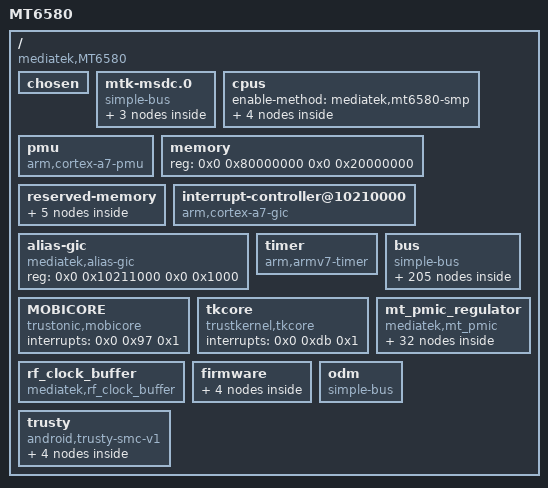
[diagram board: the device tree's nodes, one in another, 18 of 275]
/dts-v1/;

/ {
	model = "MT6580";
	compatible = "mediatek,MT6580";
	interrupt-parent = <0x1>;
	#address-cells = <0x2>;
	#size-cells = <0x2>;

	chosen {
		bootargs = "console=tty0 console=ttyMT0,921600n1 root=/dev/ram initrd=0x84000000,0x400000 loglevel=8";
		linux,phandle = <0x1e>;
		phandle = <0x1e>;
	};

	mtk-msdc.0 {
		compatible = "simple-bus";
		#address-cells = <0x1>;
		#size-cells = <0x1>;
		ranges = <0x0 0x0 0x0 0xffffffff>;

		msdc0@11120000 {
			compatible = "mediatek,mt6580-mmc";
			reg = <0x11120000 0x10000 0x10001e84 0x2>;
			interrupts = <0x0 0x26 0x8>;
			status = "disabled";
			linux,phandle = <0x1f>;
			phandle = <0x1f>;
		};

		msdc1@11130000 {
			compatible = "mediatek,mt6580-mmc";
			reg = <0x11130000 0x10000 0x10001e84 0x2>;
			interrupts = <0x0 0x27 0x8>;
			cd-gpios = <0x2 0x3 0x0>;
			status = "disabled";
			linux,phandle = <0x20>;
			phandle = <0x20>;
		};

		default {
			compatible = "mediatek,msdc1_ins-eint";
			linux,phandle = <0x21>;
			phandle = <0x21>;
		};
	};

	cpus {
		#address-cells = <0x1>;
		#size-cells = <0x0>;
		enable-method = "mediatek,mt6580-smp";

		cpu@0 {
			device_type = "cpu";
			compatible = "arm,cortex-a7";
			reg = <0x0>;
			clock-frequency = <0x6553f100>;
			linux,phandle = <0x22>;
			phandle = <0x22>;
		};

		cpu@1 {
			device_type = "cpu";
			compatible = "arm,cortex-a7";
			reg = <0x1>;
			clock-frequency = <0x6553f100>;
			linux,phandle = <0x23>;
			phandle = <0x23>;
		};

		cpu@2 {
			device_type = "cpu";
			compatible = "arm,cortex-a7";
			reg = <0x2>;
			clock-frequency = <0x6553f100>;
			linux,phandle = <0x24>;
			phandle = <0x24>;
		};

		cpu@3 {
			device_type = "cpu";
			compatible = "arm,cortex-a7";
			reg = <0x3>;
			clock-frequency = <0x6553f100>;
			linux,phandle = <0x25>;
			phandle = <0x25>;
		};
	};

	pmu {
		compatible = "arm,cortex-a7-pmu";
		interrupts = <0x0 0x4 0x8 0x0 0x5 0x8 0x0 0x6 0x8 0x0 0x7 0x8>;
	};

	memory {
		device_type = "memory";
		reg = <0x0 0x80000000 0x0 0x20000000>;
	};

	reserved-memory {
		#address-cells = <0x2>;
		#size-cells = <0x2>;
		ranges;
		linux,phandle = <0x26>;
		phandle = <0x26>;

		consys-reserve-memory {
			compatible = "mediatek,consys-reserve-memory";
			no-map;
			size = <0x0 0x200000>;
			alignment = <0x0 0x200000>;
		};

		reserve-memory-ccci_md1 {
			compatible = "mediatek,reserve-memory-ccci_md1";
			no-map;
			size = <0x0 0x1800000>;
			alignment = <0x0 0x2000000>;
			alloc-ranges = <0x0 0x80000000 0x0 0x80000000>;
		};

		pstore-reserved-memory@83f10000 {
			compatible = "mediatek,pstore";
			reg = <0x0 0x83f10000 0x0 0xe0000>;
		};

		ram_console-reserved-memory@83f00000 {
			compatible = "mediatek,ram_console";
			reg = <0x0 0x83f00000 0x0 0x10000>;
		};

		minirdump-reserved-memory@83ff0000 {
			compatible = "mediatek, minirdump";
			reg = <0x0 0x83ff0000 0x0 0x10000>;
		};
	};

	interrupt-controller@10210000 {
		compatible = "arm,cortex-a7-gic";
		#interrupt-cells = <0x3>;
		#address-cells = <0x0>;
		interrupt-controller;
		reg = <0x0 0x10211000 0x0 0x1000 0x0 0x10212000 0x0 0x1000 0x0 0x10200100 0x0 0x1000>;
		interrupts = <0x1 0x9 0xf04>;
		linux,phandle = <0x1>;
		phandle = <0x1>;
	};

	alias-gic {
		compatible = "mediatek,alias-gic";
		reg = <0x0 0x10211000 0x0 0x1000>;
	};

	timer {
		compatible = "arm,armv7-timer";
		interrupts = <0x1 0xd 0x8 0x1 0xe 0x8 0x1 0xb 0x8 0x1 0xa 0x8>;
		clock-frequency = <0xc65d40>;
	};

	bus {
		compatible = "simple-bus";
		#address-cells = <0x1>;
		#size-cells = <0x1>;
		ranges = <0x0 0x0 0x0 0xffffffff>;
		linux,phandle = <0x27>;
		phandle = <0x27>;

		chipid@08000000 {
			compatible = "mediatek,chipid";
			reg = <0x8000000 0x4 0x8000004 0x4 0x8000008 0x4 0x800000c 0x4>;
		};

		TOPCKGEN@0x10000000 {
			compatible = "mediatek,TOPCKGEN";
			reg = <0x10000000 0x1000>;
		};

		INFRACFG_AO@0x10001000 {
			compatible = "mediatek,INFRACFG_AO";
			reg = <0x10001000 0x1000>;
		};

		bat_meter {
			compatible = "mediatek,bat_meter";
			linux,phandle = <0x28>;
			phandle = <0x28>;
		};

		BAT_NOTIFY {
			compatible = "mediatek,bat_notify";
		};

		bat_comm {
			compatible = "mediatek,battery";
			linux,phandle = <0x29>;
			phandle = <0x29>;
		};

		keypad@10002000 {
			compatible = "mediatek,mt6580-keypad";
			reg = <0x10002000 0x1000>;
			interrupts = <0x0 0x6d 0x2>;
			linux,phandle = <0x2a>;
			phandle = <0x2a>;
		};

		PERICFG@0x10003000 {
			compatible = "mediatek,PERICFG";
			reg = <0x10003000 0x1000>;
		};

		RESERVED@0x10004000 {
			compatible = "mediatek,RESERVED";
			reg = <0x10004000 0x1000>;
		};

		gpio {
			compatible = "mediatek,gpio_usage_mapping";
			linux,phandle = <0x2b>;
			phandle = <0x2b>;
		};

		gpio@0x10005000 {
			compatible = "mediatek,gpio";
			reg = <0x10005000 0x1000>;
			linux,phandle = <0x2c>;
			phandle = <0x2c>;
		};

		SLEEP@0x10006000 {
			compatible = "mediatek,SLEEP";
			reg = <0x10006000 0x1000>;
			interrupts = <0x0 0x58 0x8 0x0 0x59 0x8 0x0 0x5a 0x8 0x0 0x5b 0x8>;
		};

		TOPRGU@0x10007000 {
			compatible = "mediatek,TOPRGU";
			reg = <0x10007000 0x1000>;
			interrupts = <0x0 0x9d 0x2>;
		};

		APXGPT@0x10008000 {
			compatible = "mediatek,APXGPT";
			reg = <0x10008000 0x1000>;
			interrupts = <0x0 0x5c 0x8>;
			clock-frequency = <0xc65d40>;
		};

		EFUSEC@0x10009000 {
			compatible = "mediatek,EFUSEC";
			reg = <0x10009000 0x1000>;
		};

		hacc@0x1000A000 {
			compatible = "mediatek,hacc";
			reg = <0x1000a000 0x1000>;
			interrupts = <0x0 0x6e 0x0>;
		};

		cpu_dbgapb@10170000 {
			compatible = "mediatek,hw_dbg";
			num = <0x4>;
			reg = <0x10170000 0x2000 0x10172000 0x2000 0x10174000 0x2000 0x10176000 0x2000>;
			linux,phandle = <0x2d>;
			phandle = <0x2d>;
		};

		eintc@1000b000 {
			compatible = "mediatek,mt-eic";
			reg = <0x1000b000 0x1000>;
			interrupts = <0x0 0x5e 0x4>;
			#interrupt-cells = <0x2>;
			interrupt-controller;
			mediatek,max_eint_num = <0x1a>;
			mediatek,mapping_table_entry = <0x53>;
			mediatek,mapping_table = <0x0 0x0 0x1 0x1 0x2 0x2 0x3 0x3 0x4 0x4 0x5 0x5 0x6 0x6 0x7 0x7 0x8 0x8 0x9 0x9 0xa 0xa 0xb 0xb 0xc 0xc 0xd 0xd 0xe 0xe 0xf 0xf 0x10 0x0 0x11 0x1 0x12 0x2 0x13 0x3 0x14 0x4 0x15 0x5 0x16 0x6 0x17 0x7 0x18 0x8 0x19 0x9 0x1a 0xa 0x1b 0xb 0x1c 0xc 0x1d 0xd 0x1e 0xe 0x1f 0xf 0x20 0x0 0x21 0x1 0x22 0x2 0x23 0x3 0x24 0x4 0x25 0x5 0x26 0x6 0x27 0x7 0x28 0x8 0x29 0x9 0x2a 0xa 0x2b 0xb 0x2c 0xc 0x2d 0xd 0x2e 0xe 0x2f 0xf 0x30 0x0 0x31 0x1 0x32 0x2 0x33 0x3 0x34 0x3 0x35 0x4 0x36 0x5 0x37 0x6 0x38 0x7 0x39 0x8 0x3a 0xa 0x3b 0xb 0x3c 0xc 0x3d 0xd 0x3e 0xe 0x3f 0xf 0x40 0x0 0x41 0x1 0x42 0x2 0x43 0x3 0x44 0x10 0x45 0x4 0x46 0x5 0x47 0x6 0x48 0x7 0x49 0x8 0x4a 0x9 0x4b 0xa 0x4c 0xb 0x4d 0xc 0x4e 0xd 0x51 0x0 0x52 0x1 0x53 0x2 0x54 0x3>;
			mediatek,builtin_entry = <0xb>;
			mediatek,builtin_mapping = <0x0 0x3 0x14 0x1 0x3 0x12 0x7 0x4 0x14 0x8 0x4 0x12 0x9 0x3 0x14 0xa 0x3 0x12 0x18 0x5 0x14 0x19 0x5 0x12 0x4d 0x2 0x14 0x4e 0x2 0x12 0xd 0x1 0x11>;
			linux,phandle = <0x3>;
			phandle = <0x3>;

			pmic@13 {
				compatible = "mediatek, pmic-eint";
				interrupt-parent = <0x3>;
				interrupts = <0xd 0x4>;
				debounce = <0xd 0x3e8>;
			};
		};

		ap_ccif0@1000C000 {
			compatible = "mediatek,ap_ccif0";
			reg = <0x1000c000 0x1000 0x1000d000 0x1000>;
			interrupts = <0x0 0x5d 0x8 0x0 0x98 0x2>;
			mediatek,ccif_capability = <0x2>;
			mediatek,md_smem_size = <0x200000>;
			linux,phandle = <0x2e>;
			phandle = <0x2e>;
		};

		MCUSYS_CFGREG@0x1020000 {
			compatible = "mediatek,MCUSYS_CFGREG_BASE";
			reg = <0x1020000 0x200>;
		};

		mcucfg@10200000 {
			compatible = "mediatek,mt6580-mcucfg";
			reg = <0x10200000 0x200>;
			linux,phandle = <0x2f>;
			phandle = <0x2f>;
		};

		AES@0x1000E000 {
			compatible = "mediatek,AES";
			reg = <0x1000e000 0x1000>;
		};

		PWRAP@0x1000F000 {
			compatible = "mediatek,PWRAP";
			reg = <0x1000f000 0x1000>;
			interrupts = <0x0 0x6c 0x0>;
		};

		DEVAPC_AO@0x10010000 {
			compatible = "mediatek,DEVAPC_AO";
			reg = <0x10010000 0x1000>;
		};

		MIPI_CONFG@0x10011000 {
			compatible = "mediatek,MIPI_CONFG";
			reg = <0x10011000 0x1000>;
		};

		INFRA_MBIST@0x10012000 {
			compatible = "mediatek,INFRA_MBIST";
			reg = <0x10012000 0x1000>;
		};

		RESERVED@0x10013000 {
			compatible = "mediatek,RESERVED";
			reg = <0x10013000 0x1000>;
		};

		IOCFG_T@0x10014000 {
			compatible = "mediatek,IOCFG_T";
			reg = <0x10014000 0x1000>;
		};

		IOCFG_B@0x10015000 {
			compatible = "mediatek,IOCFG_B";
			reg = <0x10015000 0x1000>;
		};

		IOCFG_L@0x10016000 {
			compatible = "mediatek,IOCFG_L";
			reg = <0x10016000 0x1000>;
		};

		IOCFG_R@0x10017000 {
			compatible = "mediatek,IOCFG_R";
			reg = <0x10017000 0x1000>;
		};

		APMIXED@0x10018000 {
			compatible = "mediatek,APMIXED";
			reg = <0x10018000 0x1000>;
		};

		MCUCFG@0x10200000 {
			compatible = "mediatek,MCUCFG";
			reg = <0x10200000 0x1000>;
		};

		INFRACFG@0x10201000 {
			compatible = "mediatek,INFRACFG";
			reg = <0x10201000 0x1000>;
		};

		sys_cirq@10202000 {
			compatible = "mediatek,mt6580-sys_cirq", "mediatek,mt6735-sys_cirq";
			reg = <0x10202000 0x1000>;
			interrupts = <0x0 0x9e 0x8>;
			mediatek,cirq_num = <0x7e>;
			mediatek,spi_start_offset = <0x20>;
			linux,phandle = <0x30>;
			phandle = <0x30>;
		};

		m4u@10203000 {
			cell-index = <0x0>;
			compatible = "mediatek,m4u";
			reg = <0x10203000 0x1000>;
			interrupts = <0x0 0x51 0x8>;
		};

		DEVAPC@0x10204000 {
			compatible = "mediatek,DEVAPC";
			reg = <0x10204000 0x1000>;
			interrupts = <0x0 0x4a 0x8>;
		};

		EMI@0x10205000 {
			compatible = "mediatek,EMI";
			reg = <0x10205000 0x1000>;
			interrupts = <0x0 0x4c 0x4>;
		};

		DRAMC_NAO@0x10206000 {
			compatible = "mediatek,DRAMC_NAO";
			reg = <0x10206000 0x1000>;
		};

		DRAMC0@0x10207000 {
			compatible = "mediatek,DRAMC0";
			reg = <0x10207000 0x1000>;
		};

		DDRPHY@0x10208000 {
			compatible = "mediatek,DDRPHY";
			reg = <0x10208000 0x1000>;
		};

		SRAMROM@0x10209000 {
			compatible = "mediatek,SRAMROM";
			reg = <0x10209000 0x1000>;
		};

		gce@1020a000 {
			compatible = "mediatek,gce";
			reg = <0x1020a000 0x1000>;
			interrupts = <0x0 0x55 0x8 0x0 0x56 0x8>;
			disp_mutex_reg = <0x14015000 0x1000>;
			g3d_config_base = <0x13000000 0x0 0xffff0000>;
			mmsys_config_base = <0x14000000 0x1 0xffff0000>;
			disp_dither_base = <0x14010000 0x2 0xffff0000>;
			mm_na_base = <0x14020000 0x3 0xffff0000>;
			imgsys_base = <0x15000000 0x4 0xffff0000>;
			vdec_gcon_base = <0x16000000 0x5 0xffff0000>;
			venc_gcon_base = <0x17000000 0x6 0xffff0000>;
			conn_peri_base = <0x18000000 0x7 0xffff0000>;
			topckgen_base = <0x10000000 0x8 0xffff0000>;
			kp_base = <0x10010000 0x9 0xffff0000>;
			scp_sram_base = <0x10020000 0xa 0xffff0000>;
			infra_na3_base = <0x10030000 0xb 0xffff0000>;
			infra_na4_base = <0x10040000 0xc 0xffff0000>;
			scp_base = <0x10050000 0xd 0xffff0000>;
			mcucfg_base = <0x10200000 0xe 0xffff0000>;
			gcpu_base = <0x10210000 0xf 0xffff0000>;
			usb0_base = <0x11200000 0x10 0xffff0000>;
			usb_sif_base = <0x11210000 0x11 0xffff0000>;
			audio_base = <0x11220000 0x12 0xffff0000>;
			msdc0_base = <0x11230000 0x13 0xffff0000>;
			msdc1_base = <0x11240000 0x14 0xffff0000>;
			msdc2_base = <0x11250000 0x15 0xffff0000>;
			msdc3_base = <0x11260000 0x16 0xffff0000>;
			pwm_sw_base = <0x1100f000 0x63 0xfffff000>;
			mdp_rdma0_sof = <0x0>;
			mdp_rsz0_sof = <0x1>;
			mdp_rsz1_sof = <0x2>;
			mdp_tdshp_sof = <0x3>;
			mdp_wdma_sof = <0x4>;
			mdp_wrot_sof = <0x5>;
			disp_ovl0_sof = <0x6>;
			disp_rdma0_sof = <0x8>;
			disp_wdma0_sof = <0xa>;
			disp_color_sof = <0xc>;
			disp_aal_sof = <0xd>;
			disp_gamma_sof = <0xe>;
			disp_dither_sof = <0xf>;
			disp_pwm0_sof = <0x11>;
			mdp_rdma0_frame_done = <0x12>;
			mdp_rsz0_frame_done = <0x13>;
			mdp_rsz1_frame_done = <0x14>;
			mdp_tdshp_frame_done = <0x15>;
			mdp_wdma_frame_done = <0x16>;
			mdp_wrot_write_frame_done = <0x17>;
			mdp_wrot_read_frame_done = <0x18>;
			disp_ovl0_frame_done = <0x19>;
			disp_rdma0_frame_done = <0x1b>;
			disp_wdma0_frame_done = <0x1d>;
			disp_color_frame_done = <0x1f>;
			disp_aal_frame_done = <0x20>;
			disp_gamma_frame_done = <0x21>;
			disp_dither_frame_done = <0x22>;
			disp_dsi0_frame_done = <0x25>;
			stream_done_0 = <0x26>;
			stream_done_1 = <0x27>;
			stream_done_2 = <0x28>;
			stream_done_3 = <0x29>;
			stream_done_4 = <0x2a>;
			stream_done_5 = <0x2b>;
			stream_done_6 = <0x2c>;
			stream_done_7 = <0x2d>;
			stream_done_8 = <0x2e>;
			stream_done_9 = <0x2f>;
			buf_underrun_event_0 = <0x30>;
			dsi0_te_event = <0x32>;
			isp_frame_done_p2_1 = <0x42>;
			isp_frame_done_p2_0 = <0x43>;
			seninf_cam0_fifo_full = <0x49>;
			apxgpt2_count = <0x10008028>;
		};

		bus_dbg@1020b000 {
			compatible = "mediatek,bus_dbg-v2";
			reg = <0x1020b000 0x1000>;
			interrupts = <0x0 0x49 0x8>;
			two_stage_timeout = <0x1>;
		};

		TRNG@0x1020C000 {
			compatible = "mediatek,TRNG";
			reg = <0x1020c000 0x1000>;
			interrupts = <0x0 0x57 0x8>;
		};

		MCUCFG_BIU@0x1020D000 {
			compatible = "mediatek,MCUCFG_BIU";
			reg = <0x1020d000 0x1000>;
		};

		DBGSYS_DEM@0x1011A000 {
			compatible = "mediatek,DBGSYS_DEM";
			reg = <0x1011a000 0x1000>;
		};

		DBGSYS_CTI@0x10112000 {
			compatible = "mediatek,DBGSYS_CTI";
			reg = <0x10112000 0x1000>;
		};

		DBGSYS_DAPROM@0x10110000 {
			compatible = "mediatek,DBGSYS_DAPROM";
			reg = <0x10110000 0x1000>;
		};

		DBGSYS_CPU@0x10160000 {
			compatible = "mediatek,DBGSYS_CPU";
			reg = <0x10160000 0x20000>;
		};

		DBGSYS_MDSYS@0x10120000 {
			compatible = "mediatek,DBGSYS_MDSYS";
			reg = <0x10120000 0x10000>;
		};

		dma@0x11000000 {
			compatible = "mediatek,ap_dma";
			reg = <0x11000000 0x1000>;
			interrupts = <0x0 0x30 0x8>;
			linux,phandle = <0x31>;
			phandle = <0x31>;
		};

		NFI@0x11001000 {
			compatible = "mediatek,NFI";
			reg = <0x11001000 0x1000>;
			interrupts = <0x0 0x2f 0x8>;
		};

		NFIECC@0x11002000 {
			compatible = "mediatek,NFIECC";
			reg = <0x11002000 0x1000>;
			interrupts = <0x0 0x2e 0x8>;
		};

		adc_hw@11003000 {
			compatible = "mediatek,mt6735-auxadc";
			reg = <0x11003000 0x1000>;
			interrupts = <0x0 0x23 0x2>;
			linux,phandle = <0x32>;
			phandle = <0x32>;
		};

		FHCTL@0x11004000 {
			compatible = "mediatek,FHCTL";
			reg = <0x11004000 0x1000>;
		};

		AP_UART0@0x11005000 {
			cell-index = <0x0>;
			compatible = "mediatek,AP_UART0";
			reg = <0x11005000 0x1000>;
			interrupts = <0x0 0x2c 0x8>;
		};

		AP_UART1@0x11006000 {
			cell-index = <0x1>;
			compatible = "mediatek,AP_UART1";
			reg = <0x11006000 0x1000>;
			interrupts = <0x0 0x2d 0x8>;
		};

		AP_DMA_UART0_TX@0x11000480 {
			compatible = "mediatek,AP_DMA_UART0_TX";
			reg = <0x11000480 0x80>;
			interrupts = <0x0 0x38 0x8>;
		};

		AP_DMA_UART0_RX@0x11000500 {
			compatible = "mediatek,AP_DMA_UART0_RX";
			reg = <0x11000500 0x80>;
			interrupts = <0x0 0x39 0x8>;
		};

		AP_DMA_UART1_TX@0x11000580 {
			compatible = "mediatek,AP_DMA_UART1_TX";
			reg = <0x11000580 0x80>;
			interrupts = <0x0 0x3a 0x8>;
		};

		AP_DMA_UART1_RX@0x11000600 {
			compatible = "mediatek,AP_DMA_UART1_RX";
			reg = <0x11000600 0x80>;
			interrupts = <0x0 0x3b 0x8>;
		};

		PWM@0x11008000 {
			compatible = "mediatek,PWM";
			reg = <0x11008000 0x1000>;
			interrupts = <0x0 0x24 0x8>;
		};

		syscfg_pctl_a@0x10005000 {
			compatible = "mediatek,mt6580-pctl-a-syscfg", "syscon";
			reg = <0x10211000 0x1000>;
			linux,phandle = <0x4>;
			phandle = <0x4>;
		};

		pinctrl@0x10005000 {
			compatible = "mediatek,mt6580-pinctrl";
			reg = <0x10005000 0x1000>;
			mediatek,pctl-regmap = <0x4>;
			pins-are-numbered;
			gpio-controller;
			#gpio-cells = <0x2>;
			linux,phandle = <0x2>;
			phandle = <0x2>;
		};

		i2c@11009000 {
			compatible = "mediatek,mt6580-i2c", "mediatek,i2c0";
			cell-index = <0x0>;
			reg = <0x11009000 0x1000>;
			interrupts = <0x0 0x28 0x8 0x0 0x32 0x8>;
			clock-div = <0xa>;
			#address-cells = <0x1>;
			#size-cells = <0x0>;
			linux,phandle = <0x33>;
			phandle = <0x33>;
		};

		i2c@1100a000 {
			compatible = "mediatek,mt6580-i2c", "mediatek,i2c1";
			cell-index = <0x1>;
			reg = <0x1100a000 0x1000>;
			interrupts = <0x0 0x29 0x8 0x0 0x33 0x8>;
			clock-div = <0xa>;
			#address-cells = <0x1>;
			#size-cells = <0x0>;
			linux,phandle = <0x34>;
			phandle = <0x34>;
		};

		i2c@1100b000 {
			compatible = "mediatek,mt6580-i2c", "mediatek,i2c2";
			cell-index = <0x2>;
			reg = <0x1100b000 0x1000>;
			interrupts = <0x0 0x2a 0x8 0x0 0x34 0x8>;
			clock-div = <0xa>;
			#address-cells = <0x1>;
			#size-cells = <0x0>;
			linux,phandle = <0x35>;
			phandle = <0x35>;
		};

		touch@0 {
			compatible = "mediatek,mt6580-touch";
			vtouch-supply = <0x5>;
			linux,phandle = <0x36>;
			phandle = <0x36>;
		};

		accdet {
			compatible = "mediatek,mt6580-accdet";
			linux,phandle = <0x37>;
			phandle = <0x37>;
		};

		gse_1 {
			compatible = "mediatek, gse_1-eint";
			status = "disabled";
			linux,phandle = <0x38>;
			phandle = <0x38>;
		};

		spi@1100c000 {
			compatible = "mediatek,mt6580-spi";
			cell-index = <0x0>;
			reg = <0x1100c000 0x1000>;
			interrupts = <0x0 0x40 0x8>;
			mediatek,spi-padmacro = <0x0>;
		};

		THERM_CTRL@0x1100D000 {
			compatible = "mediatek,THERM_CTRL";
			reg = <0x1100d000 0x1000>;
			interrupts = <0x0 0x25 0x8>;
		};

		btif_tx@11000380 {
			compatible = "mediatek,btif_tx";
			reg = <0x11000380 0x80>;
			interrupts = <0x0 0x36 0x8>;
			linux,phandle = <0x39>;
			phandle = <0x39>;
		};

		btif_rx@11000400 {
			compatible = "mediatek,btif_rx";
			reg = <0x11000400 0x80>;
			interrupts = <0x0 0x37 0x8>;
			linux,phandle = <0x3a>;
			phandle = <0x3a>;
		};

		btif@1100e000 {
			compatible = "mediatek,btif";
			reg = <0x1100e000 0x1000>;
			interrupts = <0x0 0x43 0x8>;
			linux,phandle = <0x3b>;
			phandle = <0x3b>;
		};

		gps {
			compatible = "mediatek,gps";
		};

		BTCVSD@0x10001000 {
			compatible = "mediatek,audio_bt_cvsd";
			offset = <0xc00 0x2 0xfd0 0xfd4 0xfd8>;
			reg = <0x10001000 0x1000 0x18000000 0x10000 0x18080000 0x8000>;
			interrupts = <0x0 0x99 0x8>;
		};

		consys@18070000 {
			compatible = "mediatek,mt6580-consys";
			reg = <0x18070000 0x200 0x10007000 0x100 0x10000000 0x2000 0x10006000 0x1000 0x10005000 0x1000>;
			interrupts = <0x0 0x9a 0x8 0x0 0x9c 0x8>;
			vcn18-supply = <0x6>;
			vcn28-supply = <0x7>;
			vcn33_bt-supply = <0x8>;
			vcn33_wifi-supply = <0x9>;
			linux,phandle = <0x3c>;
			phandle = <0x3c>;
		};

		WIFI@0x180F0000 {
			compatible = "mediatek,WIFI";
			reg = <0x180f0000 0x5c>;
			interrupts = <0x0 0x9b 0x8>;
		};

		DISP_PWM@0x1100F000 {
			compatible = "mediatek,DISP_PWM";
			reg = <0x1100f000 0x1000>;
			interrupts = <0x0 0x21 0x8>;
		};

		USB0@0x11100000 {
			compatible = "mediatek,USB0";
			cell-index = <0x0>;
			reg = <0x11100000 0x10000 0x11110000 0x10000>;
			interrupts = <0x0 0x20 0x8>;
			mode = <0x2>;
			multipoint = <0x1>;
			dyn_fifo = <0x1>;
			soft_con = <0x1>;
			dma = <0x1>;
			num_eps = <0x10>;
			dma_channels = <0x8>;
			iddig_gpio = <0x9 0x3>;
			drvvbus_gpio = <0xe 0x7>;
			linux,phandle = <0x3d>;
			phandle = <0x3d>;

			usbiddig {
				compatible = "mediatek,usb_iddig_eint";
				linux,phandle = <0x3e>;
				phandle = <0x3e>;
			};
		};

		usbphy@0 {
			compatible = "usb-nop-xceiv";
			linux,phandle = <0x3f>;
			phandle = <0x3f>;
		};

		usb_c_pinctrl@0 {
			compatible = "mediatek,usb_c_pinctrl";
			linux,phandle = <0x40>;
			phandle = <0x40>;
		};

		audio@11140000 {
			compatible = "mediatek,audio";
			reg = <0x11140000 0x10000>;
			interrupts = <0x0 0x50 0x8>;
		};

		mt_soc_dl1_pcm@11140000 {
			compatible = "mediatek,mt_soc_pcm_dl1";
			reg = <0x11140000 0x1000>;
			interrupts = <0x0 0x50 0x8>;
			audclk-gpio = <0x1a 0x0>;
			audmiso-gpio = <0x1c 0x0>;
			audmosi-gpio = <0x1b 0x0>;
			linux,phandle = <0x41>;
			phandle = <0x41>;
		};

		mt_soc_ul1_PCM {
			compatible = "mediatek,mt_soc_pcm_capture";
		};

		mt_soc_voice_md1 {
			compatible = "mediatek,mt_soc_pcm_voice_md1";
		};

		mt_soc_hdmi_pcm {
			compatible = "mediatek,mt_soc_pcm_hdmi";
		};

		mt_soc_uldlloopback_pcm {
			compatible = "mediatek,mt_soc_pcm_uldlloopback";
		};

		mt_soc_i2s0_pcm {
			compatible = "mediatek,mt_soc_pcm_dl1_i2s0";
		};

		mt_soc_mrgrx_pcm {
			compatible = "mediatek,mt_soc_pcm_mrgrx";
		};

		mt_soc_mrgrx_awb_pcm {
			compatible = "mediatek,mt_soc_pcm_mrgrx_awb";
		};

		mt_soc_fm_i2s_pcm {
			compatible = "mediatek,mt_soc_pcm_fm_i2s";
		};

		mt_soc_fm_i2s_awb_pcm {
			compatible = "mediatek,mt_soc_pcm_fm_i2s_awb";
		};

		mt_soc_i2s0dl1_pcm {
			compatible = "mediatek,mt_soc_pcm_dl1_i2s0Dl1";
		};

		mt_soc_deep_buffer_dl_pcm {
			compatible = "mediatek,mt_soc_pcm_deep_buffer_dl";
		};

		mt_soc_dl1_awb_pcm {
			compatible = "mediatek,mt_soc_pcm_dl1_awb";
		};

		mt_soc_voice_md1_bt {
			compatible = "mediatek,mt_soc_pcm_voice_md1_bt";
		};

		mt_soc_voip_bt_out {
			compatible = "mediatek,mt_soc_pcm_dl1_bt";
		};

		mt_soc_voip_bt_in {
			compatible = "mediatek,mt_soc_pcm_bt_dai";
		};

		mt_soc_tdmrx_pcm {
			compatible = "mediatek,mt_soc_tdm_capture";
		};

		mt_soc_fm_mrgtx_pcm {
			compatible = "mediatek,mt_soc_pcm_fmtx";
		};

		mt_soc_ul2_pcm {
			compatible = "mediatek,mt_soc_pcm_capture2";
		};

		mt_soc_i2s0_awb_pcm {
			compatible = "mediatek,mt_soc_pcm_i2s0_awb";
		};

		mt_soc_voice_md2 {
			compatible = "mediatek,mt_soc_pcm_voice_md2";
		};

		mt_soc_routing_pcm {
			compatible = "mediatek,mt_soc_pcm_routing";
		};

		mt_soc_voice_md2_bt {
			compatible = "mediatek,mt_soc_pcm_voice_md2_bt";
		};

		mt_soc_hp_impedance_pcm {
			compatible = "mediatek,Mt_soc_pcm_hp_impedance";
		};

		mt_soc_codec_name {
			compatible = "mediatek,mt_soc_codec_63xx";
		};

		mt_soc_dummy_pcm {
			compatible = "mediatek,mt_soc_pcm_dummy";
		};

		mt_soc_codec_dummy_name {
			compatible = "mediatek,mt_soc_codec_dummy";
		};

		mt_soc_routing_dai_name {
			compatible = "mediatek,mt_soc_dai_routing";
		};

		mt_soc_dai_name {
			compatible = "mediatek,mt_soc_dai_stub";
		};

		mt_soc_dl2_pcm {
			compatible = "mediatek,mt_soc_pcm_dl2";
		};

		AHB_MOM@0x11150000 {
			compatible = "mediatek,AHB_MOM";
			reg = <0x11150000 0x10000>;
		};

		MDI@0x11160000 {
			compatible = "mediatek,MDI";
			reg = <0x11160000 0x10000>;
		};

		G3D_CONFIG@0x13000000 {
			compatible = "mediatek,G3D_CONFIG";
			reg = <0x13000000 0x1000>;
		};

		MALI@0x13010000 {
			compatible = "mediatek,MALI";
			reg = <0x13010000 0x10000>;
		};

		mmsys_config@14000000 {
			compatible = "mediatek,mmsys_config";
			reg = <0x14000000 0x1000>;
			interrupts = <0x0 0x84 0x8>;
		};

		mdp_rdma@14001000 {
			compatible = "mediatek,mdp_rdma";
			reg = <0x14001000 0x1000>;
			interrupts = <0x0 0x71 0x8>;
		};

		mdp_rsz0@14002000 {
			compatible = "mediatek,mdp_rsz0";
			reg = <0x14002000 0x1000>;
			interrupts = <0x0 0x72 0x8>;
		};

		mdp_rsz1@14003000 {
			compatible = "mediatek,mdp_rsz1";
			reg = <0x14003000 0x1000>;
			interrupts = <0x0 0x73 0x8>;
		};

		mdp_wdma@14004000 {
			compatible = "mediatek,mdp_wdma";
			reg = <0x14004000 0x1000>;
			interrupts = <0x0 0x75 0x8>;
		};

		mdp_wrot@14005000 {
			compatible = "mediatek,mdp_wrot";
			reg = <0x14005000 0x1000>;
			interrupts = <0x0 0x76 0x8>;
		};

		mdp_tdshp@14006000 {
			compatible = "mediatek,mdp_tdshp";
			reg = <0x14006000 0x1000>;
			interrupts = <0x0 0x74 0x8>;
		};

		lcm {
			compatible = "mediatek,mt6580-lcm";
			linux,phandle = <0x42>;
			phandle = <0x42>;
		};

		nfc {
			compatible = "mediatek,nfc-gpio-v2";
			gpio-ven = <0xb>;
			gpio-rst = <0xa>;
			gpio-eint = <0xc>;
			gpio-irq = <0x9>;
			linux,phandle = <0x43>;
			phandle = <0x43>;
		};

		DISPSYS@0x14007000 {
			compatible = "mediatek,DISPSYS";
			reg = <0x14000000 0x1000 0x14007000 0x1000 0x14008000 0x1000 0x14009000 0x1000 0x1400a000 0x1000 0x1400b000 0x1000 0x1400c000 0x1000 0x1400d000 0x1000 0x1400e000 0x1000 0x1400f000 0x1000 0x14010000 0x1000 0x14011000 0x1000 0x14012000 0x1000 0x14013000 0x1000 0x1100f000 0x1000 0x14015000 0x1000 0x14016000 0x1000 0x14017000 0x1000 0x14018000 0x1000>;
			interrupts = <0x0 0x0 0x8 0x0 0x77 0x8 0x0 0x0 0x8 0x0 0x79 0x8 0x0 0x0 0x8 0x0 0x7b 0x8 0x0 0x7c 0x8 0x0 0x0 0x8 0x0 0x7e 0x8 0x0 0x7f 0x8 0x0 0x80 0x8 0x0 0x0 0x8 0x0 0x82 0x8 0x0 0x0 0x8 0x0 0x0 0x8 0x0 0x70 0x8 0x0 0x0 0x8 0x0 0x0 0x8 0x0 0x0 0x8>;
		};

		DISP_OVL0@0x14007000 {
			compatible = "mediatek,DISP_OVL0";
			reg = <0x14007000 0x1000>;
			interrupts = <0x0 0x77 0x8>;
		};

		DISP_OVL1@0x14008000 {
			compatible = "mediatek,DISP_OVL1";
			reg = <0x14008000 0x1000>;
		};

		DISP_RDMA0@0x14009000 {
			compatible = "mediatek,DISP_RDMA0";
			reg = <0x14009000 0x1000>;
			interrupts = <0x0 0x79 0x8>;
		};

		DISP_RDMA1@0x1400A000 {
			compatible = "mediatek,DISP_RDMA1";
			reg = <0x1400a000 0x1000>;
		};

		DISP_WDMA@0x1400B000 {
			compatible = "mediatek,DISP_WDMA";
			reg = <0x1400b000 0x1000>;
			interrupts = <0x0 0x7b 0x8>;
		};

		DISP_COLOR@0x1400C000 {
			compatible = "mediatek,DISP_COLOR";
			reg = <0x1400c000 0x1000>;
			interrupts = <0x0 0x7c 0x8>;
		};

		DISP_CCORR@0x1400D000 {
			compatible = "mediatek,DISP_CCORR";
			reg = <0x1400d000 0x1000>;
		};

		DISP_AAL@0x1400E000 {
			compatible = "mediatek,DISP_AAL";
			reg = <0x1400e000 0x1000>;
			interrupts = <0x0 0x7e 0x8>;
		};

		DISP_GAMMA@0x1400F000 {
			compatible = "mediatek,DISP_GAMMA";
			reg = <0x1400f000 0x1000>;
			interrupts = <0x0 0x7f 0x8>;
		};

		DISP_DITHER@0x14010000 {
			compatible = "mediatek,DISP_DITHER";
			reg = <0x14010000 0x1000>;
			interrupts = <0x0 0x80 0x8>;
		};

		DISP_UFOE@0x14011000 {
			compatible = "mediatek,DISP_UFOE";
			reg = <0x14011000 0x1000>;
		};

		DSI@0x14012000 {
			compatible = "mediatek,DSI";
			reg = <0x14012000 0x1000>;
		};

		DPI@0x14013000 {
			compatible = "mediatek,DPI";
			reg = <0x14013000 0x1000>;
		};

		PTP_FSM@0x1100D000 {
			compatible = "mediatek,PTP_FSM";
			reg = <0x1100d000 0x1000>;
			interrupts = <0x0 0x2b 0x8>;
		};

		MM_MUTEX@0x14015000 {
			compatible = "mediatek,MM_MUTEX";
			reg = <0x14015000 0x1000>;
			interrupts = <0x0 0x70 0x8>;
		};

		SMI_LARB0@0x14016000 {
			compatible = "mediatek,SMI_LARB0";
			reg = <0x14016000 0x1000>;
			interrupts = <0x0 0x85 0x8>;
		};

		SMI_COMMON@0x14017000 {
			compatible = "mediatek,SMI_COMMON";
			reg = <0x14017000 0x1000 0x14016000 0x1000 0x15001000 0x1000>;
		};

		MIPI_TX_CONFIG@0x14018000 {
			compatible = "mediatek,MIPI_TX_CONFIG";
			reg = <0x14018000 0x1000>;
		};

		ISPSYS@0x15000000 {
			compatible = "mediatek,ISPSYS";
			reg = <0x15004000 0x9000 0x15000000 0x10000 0x10011000 0x4000 0x10017000 0x1000>;
			interrupts = <0x0 0x8e 0x8 0x0 0x8b 0x8>;
		};

		ISP_SYSR@0x15000000 {
			compatible = "mediatek,ISP_SYSR";
		};

		ISP_PIPEM@0x15000000 {
			compatible = "mediatek,ISP_PIPEM";
		};

		kd_camera_hw1@15008000 {
			compatible = "mediatek,camera_hw";
			reg = <0x15008000 0x1000>;
			vcama-supply = <0xa>;
			vcamd-supply = <0xb>;
			vcamaf-supply = <0xc>;
			vcamio-supply = <0xd>;
			linux,phandle = <0x44>;
			phandle = <0x44>;
		};

		kd_camera_hw2@15008000 {
			compatible = "mediatek,camera_hw2";
			reg = <0x15008000 0x1000>;
			linux,phandle = <0x45>;
			phandle = <0x45>;
		};

		seninf_top@15008000 {
			compatible = "mediatek,SENINF_TOP";
			reg = <0x15008000 0x1000>;
			interrupts = <0x0 0x8e 0x8>;
		};

		CAM_0@0x15004000 {
			compatible = "mediatek,CAM_0";
			reg = <0x15004000 0x1000>;
			interrupts = <0x0 0x8b 0x8>;
		};

		CAM_1@0x15005000 {
			compatible = "mediatek,CAM_1";
			reg = <0x15005000 0x1000>;
		};

		VENC@0x15009000 {
			compatible = "mediatek,VENC";
			reg = <0x15009000 0x1000>;
			interrupts = <0x0 0x8a 0x8>;
		};

		VDEC@0x1500B000 {
			compatible = "mediatek,VDEC";
			reg = <0x1500b000 0x1000>;
			interrupts = <0x0 0x89 0x8>;
		};

		SMI_LARB1@0x15001000 {
			compatible = "mediatek,SMI_LARB1";
			reg = <0x15001000 0x1000>;
			interrupts = <0x0 0x88 0x8>;
		};

		IMGSYS_CONFIG@0x15000000 {
			compatible = "mediatek,IMGSYS_CONFIG";
			reg = <0x15000000 0x1000>;
		};

		hwmsensor@0 {
			compatible = "mediatek,hwmsensor";
		};

		gsensor@0 {
			compatible = "mediatek,gsensor";
		};

		als_ps@0 {
			compatible = "mediatek,als_ps";
			linux,phandle = <0x46>;
			phandle = <0x46>;
		};

		m_acc_pl@0 {
			compatible = "mediatek,m_acc_pl";
		};

		m_alsps_pl@0 {
			compatible = "mediatek,m_alsps_pl";
		};

		sensorHub@0 {
			compatible = "mediatek,sensorHub";
		};

		shf@0 {
			compatible = "mediatek,shf";
		};

		m_batch_pl@0 {
			compatible = "mediatek,m_batch_pl";
		};

		gyroscope@0 {
			compatible = "mediatek,gyroscope";
			linux,phandle = <0x47>;
			phandle = <0x47>;
		};

		m_gyro_pl@0 {
			compatible = "mediatek,m_gyro_pl";
		};

		barometer@0 {
			compatible = "mediatek,barometer";
		};

		m_baro_pl@0 {
			compatible = "mediatek,m_baro_pl";
		};

		msensor@0 {
			compatible = "mediatek,msensor";
		};

		m_mag_pl@0 {
			compatible = "mediatek,m_mag_pl";
		};

		orientation@0 {
			compatible = "mediatek,orientation";
		};

		pedometer@0 {
			compatible = "mediatek,pedometer";
		};

		m_pdr_pl@0 {
			compatible = "mediatek,m_pdr_pl";
		};

		step_counter@0 {
			compatible = "mediatek,step_counter";
		};

		m_step_c_pl@0 {
			compatible = "mediatek,m_step_c_pl";
		};

		in_pocket@0 {
			compatible = "mediatek,in_pocket";
		};

		m_inpk_pl@0 {
			compatible = "mediatek,m_inpk_pl";
		};

		shake@0 {
			compatible = "mediatek,shake";
		};

		m_shk_pl@0 {
			compatible = "mediatek,m_shk_pl";
		};

		face_down@0 {
			compatible = "mediatek,face_down";
		};

		m_fdn_pl@0 {
			compatible = "mediatek,m_fdn_pl";
		};

		activity@0 {
			compatible = "mediatek,activity";
		};

		m_act_pl@0 {
			compatible = "mediatek,m_act_pl";
		};

		heart_rate@0 {
			compatible = "mediatek,heart_rate";
		};

		m_hrm_pl@0 {
			compatible = "mediatek,m_hrm_pl";
		};

		tilt_detector@0 {
			compatible = "mediatek,tilt_detector";
		};

		m_tilt_pl@0 {
			compatible = "mediatek,m_tilt_pl";
		};

		wake_gesture@0 {
			compatible = "mediatek,wake_gesture";
		};

		m_wag_pl@0 {
			compatible = "mediatek,m_wag_pl";
		};

		glance_gesture@0 {
			compatible = "mediatek,glance_gesture";
		};

		m_glg_pl@0 {
			compatible = "mediatek,m_glg_pl";
		};

		pick_up@0 {
			compatible = "mediatek,pick_up";
		};

		m_pkup_pl@0 {
			compatible = "mediatek,m_pkup_pl";
		};

		als {
			compatible = "mediatek, als-eint";
			linux,phandle = <0x48>;
			phandle = <0x48>;
		};

		mtkfb@0 {
			compatible = "mediatek,mtkfb";
			linux,phandle = <0x49>;
			phandle = <0x49>;
		};

		dsi_te {
			compatible = "mediatek, dsi_te-eint";
			linux,phandle = <0x4a>;
			phandle = <0x4a>;
		};

		hct_finger@0 {
			compatible = "mediatek,hct_finger";
			linux,phandle = <0x4b>;
			phandle = <0x4b>;
		};

		hct_device {
			compatible = "mediatek,hct_devices";
			linux,phandle = <0x4c>;
			phandle = <0x4c>;
		};

		mtk_leds@bus {
			compatible = "mediatek,mtk_leds";
			linux,phandle = <0x4d>;
			phandle = <0x4d>;
		};

		kpd_slide@0 {
			compatible = "mediatek,hct-hall";
			linux,phandle = <0x4e>;
			phandle = <0x4e>;
		};
	};

	MOBICORE {
		compatible = "trustonic,mobicore";
		interrupts = <0x0 0x97 0x1>;
	};

	tkcore {
		compatible = "trustkernel,tkcore";
		interrupts = <0x0 0xdb 0x1>;
	};

	mt_pmic_regulator {
		compatible = "mediatek,mt_pmic";

		buck_regulators {
			compatible = "mediatek,mt_pmic_buck_regulators";

			buck_vpa {
				regulator-name = "vpa";
				regulator-min-microvolt = <0x7a120>;
				regulator-max-microvolt = <0x37b1d0>;
				regulator-ramp-delay = <0xc350>;
				regulator-enable-ramp-delay = <0xb4>;
				linux,phandle = <0x4f>;
				phandle = <0x4f>;
			};

			buck_vproc {
				regulator-name = "vproc";
				regulator-min-microvolt = <0xaae60>;
				regulator-max-microvolt = <0x16caf6>;
				regulator-ramp-delay = <0x186a>;
				regulator-enable-ramp-delay = <0xb4>;
				regulator-always-on;
				regulator-boot-on;
				linux,phandle = <0x50>;
				phandle = <0x50>;
			};
		};

		ldo_regulators {
			compatible = "mediatek,mt_pmic_ldo_regulators";

			ldo_vcn28 {
				regulator-name = "vcn28";
				regulator-min-microvolt = <0x1b7740>;
				regulator-max-microvolt = <0x2ab980>;
				regulator-enable-ramp-delay = <0x108>;
				linux,phandle = <0x7>;
				phandle = <0x7>;
			};

			ldo_vtcxo {
				regulator-name = "vtcxo";
				regulator-min-microvolt = <0x2191c0>;
				regulator-max-microvolt = <0x2191c0>;
				regulator-enable-ramp-delay = <0x6e>;
				linux,phandle = <0xe>;
				phandle = <0xe>;
			};

			ldo_va {
				regulator-name = "va";
				regulator-min-microvolt = <0x1b7740>;
				regulator-max-microvolt = <0x2625a0>;
				regulator-enable-ramp-delay = <0x6e>;
				linux,phandle = <0xf>;
				phandle = <0xf>;
			};

			ldo_vcama {
				regulator-name = "vcama";
				regulator-min-microvolt = <0x16e360>;
				regulator-max-microvolt = <0x2ab980>;
				regulator-enable-ramp-delay = <0x108>;
				linux,phandle = <0xa>;
				phandle = <0xa>;
			};

			ldo_vcn33_bt {
				regulator-name = "vcn33_bt";
				regulator-min-microvolt = <0x325aa0>;
				regulator-max-microvolt = <0x36ee80>;
				regulator-enable-ramp-delay = <0x108>;
				linux,phandle = <0x8>;
				phandle = <0x8>;
			};

			ldo_vcn33_wifi {
				regulator-name = "vcn33_wifi";
				regulator-min-microvolt = <0x325aa0>;
				regulator-max-microvolt = <0x36ee80>;
				regulator-enable-ramp-delay = <0x108>;
				linux,phandle = <0x9>;
				phandle = <0x9>;
			};

			ldo_vio28 {
				regulator-name = "vio28";
				regulator-min-microvolt = <0x2ab980>;
				regulator-max-microvolt = <0x2ab980>;
				regulator-enable-ramp-delay = <0x108>;
				regulator-boot-on;
				linux,phandle = <0x10>;
				phandle = <0x10>;
			};

			ldo_vsim1 {
				regulator-name = "vsim1";
				regulator-min-microvolt = <0x1b7740>;
				regulator-max-microvolt = <0x2dc6c0>;
				regulator-enable-ramp-delay = <0x108>;
				linux,phandle = <0x11>;
				phandle = <0x11>;
			};

			ldo_vsim2 {
				regulator-name = "vsim2";
				regulator-min-microvolt = <0x1b7740>;
				regulator-max-microvolt = <0x2dc6c0>;
				regulator-enable-ramp-delay = <0x108>;
				linux,phandle = <0x12>;
				phandle = <0x12>;
			};

			ldo_vusb {
				regulator-name = "vusb";
				regulator-min-microvolt = <0x325aa0>;
				regulator-max-microvolt = <0x325aa0>;
				regulator-enable-ramp-delay = <0x108>;
				regulator-boot-on;
				linux,phandle = <0x13>;
				phandle = <0x13>;
			};

			ldo_vgp1 {
				regulator-name = "vgp1";
				regulator-min-microvolt = <0x124f80>;
				regulator-max-microvolt = <0x325aa0>;
				regulator-enable-ramp-delay = <0x108>;
				linux,phandle = <0x5>;
				phandle = <0x5>;
			};

			ldo_vgp2 {
				regulator-name = "vgp2";
				regulator-min-microvolt = <0x124f80>;
				regulator-max-microvolt = <0x2dc6c0>;
				regulator-enable-ramp-delay = <0x108>;
				linux,phandle = <0x14>;
				phandle = <0x14>;
			};

			ldo_vemc_3v3 {
				regulator-name = "vemc_3v3";
				regulator-min-microvolt = <0x2dc6c0>;
				regulator-max-microvolt = <0x325aa0>;
				regulator-enable-ramp-delay = <0x108>;
				regulator-boot-on;
				linux,phandle = <0x15>;
				phandle = <0x15>;
			};

			ldo_vcamaf {
				regulator-name = "vcamaf";
				regulator-min-microvolt = <0x124f80>;
				regulator-max-microvolt = <0x325aa0>;
				regulator-enable-ramp-delay = <0x108>;
				linux,phandle = <0xc>;
				phandle = <0xc>;
			};

			ldo_vmc {
				regulator-name = "vmc";
				regulator-min-microvolt = <0x1b7740>;
				regulator-max-microvolt = <0x325aa0>;
				regulator-enable-ramp-delay = <0x2c>;
				linux,phandle = <0x16>;
				phandle = <0x16>;
			};

			ldo_vmch {
				regulator-name = "vmch";
				regulator-min-microvolt = <0x2dc6c0>;
				regulator-max-microvolt = <0x325aa0>;
				regulator-enable-ramp-delay = <0x2c>;
				linux,phandle = <0x17>;
				phandle = <0x17>;
			};

			ldo_vibr {
				regulator-name = "vibr";
				regulator-min-microvolt = <0x124f80>;
				regulator-max-microvolt = <0x325aa0>;
				regulator-enable-ramp-delay = <0x2c>;
				linux,phandle = <0x18>;
				phandle = <0x18>;
			};

			ldo_vrtc {
				regulator-name = "vrtc";
				regulator-min-microvolt = <0x2ab980>;
				regulator-max-microvolt = <0x2ab980>;
				regulator-enable-ramp-delay = <0x2c>;
				linux,phandle = <0x19>;
				phandle = <0x19>;
			};

			ldo_vm {
				regulator-name = "vm";
				regulator-min-microvolt = <0x124f80>;
				regulator-max-microvolt = <0x1b7740>;
				regulator-enable-ramp-delay = <0x108>;
				regulator-boot-on;
				linux,phandle = <0x1a>;
				phandle = <0x1a>;
			};

			ldo_vrf18 {
				regulator-name = "vrf18";
				regulator-min-microvolt = <0x1b7740>;
				regulator-max-microvolt = <0x1b7740>;
				regulator-enable-ramp-delay = <0xdc>;
				linux,phandle = <0x1b>;
				phandle = <0x1b>;
			};

			ldo_vio18 {
				regulator-name = "vio18";
				regulator-min-microvolt = <0x1b7740>;
				regulator-max-microvolt = <0x1b7740>;
				regulator-enable-ramp-delay = <0x108>;
				regulator-boot-on;
				linux,phandle = <0x1c>;
				phandle = <0x1c>;
			};

			ldo_vcamd {
				regulator-name = "vcamd";
				regulator-min-microvolt = <0x124f80>;
				regulator-max-microvolt = <0x1b7740>;
				regulator-enable-ramp-delay = <0x108>;
				linux,phandle = <0xb>;
				phandle = <0xb>;
			};

			ldo_vcamio {
				regulator-name = "vcamio";
				regulator-min-microvolt = <0x1b7740>;
				regulator-max-microvolt = <0x1b7740>;
				regulator-enable-ramp-delay = <0xdc>;
				linux,phandle = <0xd>;
				phandle = <0xd>;
			};

			ldo_vgp3 {
				regulator-name = "vgp3";
				regulator-min-microvolt = <0x124f80>;
				regulator-max-microvolt = <0x1b7740>;
				regulator-enable-ramp-delay = <0x108>;
				linux,phandle = <0x1d>;
				phandle = <0x1d>;
			};

			ldo_vcn_1v8 {
				regulator-name = "vcn_1v8";
				regulator-min-microvolt = <0x1b7740>;
				regulator-max-microvolt = <0x1b7740>;
				regulator-enable-ramp-delay = <0x2c>;
				linux,phandle = <0x6>;
				phandle = <0x6>;
			};

			vcanio_ldo_reg {
				linux,phandle = <0x51>;
				phandle = <0x51>;
			};

			vcn33_ldo_reg {
				linux,phandle = <0x52>;
				phandle = <0x52>;
			};
		};

		regulators_supply {
			compatible = "mediatek,mt_pmic_regulator_supply";
			vcn28-supply = <0x7>;
			vtcxo-supply = <0xe>;
			va-supply = <0xf>;
			vcn33_bt-supply = <0x8>;
			vcn33_wifi-supply = <0x9>;
			vio28-supply = <0x10>;
			vsim1-supply = <0x11>;
			vsim2-supply = <0x12>;
			vusb-supply = <0x13>;
			vgp1-supply = <0x5>;
			vgp2-supply = <0x14>;
			vemc_3v3-supply = <0x15>;
			vcamaf-supply = <0xc>;
			vmc-supply = <0x16>;
			vmch-supply = <0x17>;
			vibr-supply = <0x18>;
			vrtc-supply = <0x19>;
			vm-supply = <0x1a>;
			vrf18-supply = <0x1b>;
			vio18-supply = <0x1c>;
			vcamd-supply = <0xb>;
			vcamio-supply = <0xd>;
			vgp3-supply = <0x1d>;
			vcn_1v8-supply = <0x6>;
		};
	};

	rf_clock_buffer {
		compatible = "mediatek,rf_clock_buffer";
		#mediatek,clkbuf-quantity = <0x4>;
		#mediatek,clkbuf-config = <0x2 0x1 0x1 0x1>;
		linux,phandle = <0x53>;
		phandle = <0x53>;
	};

	firmware {

		android {
			compatible = "android,firmware";

			fstab {
				compatible = "android,fstab";

				system {
					compatible = "android,system";
					dev = "/dev/block/platform/mtk-msdc.0/11120000.msdc0/by-name/system";
					type = "ext4";
					mnt_flags = "ro";
					fsmgr_flags = "wait";
				};

				vendor {
					compatible = "android,vendor";
					dev = "/dev/block/platform/mtk-msdc.0/11120000.msdc0/by-name/vendor";
					type = "ext4";
					mnt_flags = "ro";
					fsmgr_flags = "wait";
				};
			};
		};
	};

	odm {
		compatible = "simple-bus";
		linux,phandle = <0x54>;
		phandle = <0x54>;
	};

	trusty {
		compatible = "android,trusty-smc-v1";
		ranges;
		#address-cells = <0x2>;
		#size-cells = <0x2>;

		irq {
			compatible = "android,trusty-irq-v1";
			ppi-interrupt-parent = <0x1>;
		};

		log {
			compatible = "android,trusty-log-v1";
		};

		virtio {
			compatible = "android,trusty-virtio-v1";
		};

		mtee {
			compatible = "mediatek,trusty-mtee-v1";
		};
	};

	__symbols__ {
		chosen = "/chosen";
		mmc0 = "/mtk-msdc.0/msdc0@11120000";
		mmc1 = "/mtk-msdc.0/msdc1@11130000";
		msdc1_ins = "/mtk-msdc.0/default";
		cpu0 = "/cpus/cpu@0";
		cpu1 = "/cpus/cpu@1";
		cpu2 = "/cpus/cpu@2";
		cpu3 = "/cpus/cpu@3";
		reserved_memory = "/reserved-memory";
		gic = "/interrupt-controller@10210000";
		mtk_bus = "/bus";
		bat_meter = "/bus/bat_meter";
		bat_comm = "/bus/bat_comm";
		keypad = "/bus/keypad@10002000";
		gpio_usage_mapping = "/bus/gpio";
		gpio = "/bus/gpio@0x10005000";
		cpu_dbgapb = "/bus/cpu_dbgapb@10170000";
		eintc = "/bus/eintc@1000b000";
		ap_ccif0 = "/bus/ap_ccif0@1000C000";
		mcucfg = "/bus/mcucfg@10200000";
		sys_cirq = "/bus/sys_cirq@10202000";
		ap_dma = "/bus/dma@0x11000000";
		auxadc = "/bus/adc_hw@11003000";
		syscfg_pctl_a = "/bus/syscfg_pctl_a@0x10005000";
		pio = "/bus/pinctrl@0x10005000";
		i2c0 = "/bus/i2c@11009000";
		i2c1 = "/bus/i2c@1100a000";
		i2c2 = "/bus/i2c@1100b000";
		touch = "/bus/touch@0";
		accdet = "/bus/accdet";
		gse_1 = "/bus/gse_1";
		btif_tx = "/bus/btif_tx@11000380";
		btif_rx = "/bus/btif_rx@11000400";
		btif = "/bus/btif@1100e000";
		consys = "/bus/consys@18070000";
		usb0 = "/bus/USB0@0x11100000";
		usbiddig = "/bus/USB0@0x11100000/usbiddig";
		usbphy0 = "/bus/usbphy@0";
		usb_c_pinctrl = "/bus/usb_c_pinctrl@0";
		audgpio = "/bus/mt_soc_dl1_pcm@11140000";
		lcm = "/bus/lcm";
		nfc = "/bus/nfc";
		kd_camera_hw1 = "/bus/kd_camera_hw1@15008000";
		kd_camera_hw2 = "/bus/kd_camera_hw2@15008000";
		alsps = "/bus/als_ps@0";
		gyro = "/bus/gyroscope@0";
		als = "/bus/als";
		mtkfb = "/bus/mtkfb@0";
		dsi_te = "/bus/dsi_te";
		hct_finger = "/bus/hct_finger@0";
		hct_device = "/bus/hct_device";
		mtk_leds = "/bus/mtk_leds@bus";
		kpd_slide = "/bus/kpd_slide@0";
		mt_pmic_vpa_buck_reg = "/mt_pmic_regulator/buck_regulators/buck_vpa";
		mt_pmic_vproc_buck_reg = "/mt_pmic_regulator/buck_regulators/buck_vproc";
		mt_pmic_vcn28_ldo_reg = "/mt_pmic_regulator/ldo_regulators/ldo_vcn28";
		mt_pmic_vtcxo_ldo_reg = "/mt_pmic_regulator/ldo_regulators/ldo_vtcxo";
		mt_pmic_va_ldo_reg = "/mt_pmic_regulator/ldo_regulators/ldo_va";
		mt_pmic_vcama_ldo_reg = "/mt_pmic_regulator/ldo_regulators/ldo_vcama";
		mt_pmic_vcn33_bt_ldo_reg = "/mt_pmic_regulator/ldo_regulators/ldo_vcn33_bt";
		mt_pmic_vcn33_wifi_ldo_reg = "/mt_pmic_regulator/ldo_regulators/ldo_vcn33_wifi";
		mt_pmic_vio28_ldo_reg = "/mt_pmic_regulator/ldo_regulators/ldo_vio28";
		mt_pmic_vsim1_ldo_reg = "/mt_pmic_regulator/ldo_regulators/ldo_vsim1";
		mt_pmic_vsim2_ldo_reg = "/mt_pmic_regulator/ldo_regulators/ldo_vsim2";
		mt_pmic_vusb_ldo_reg = "/mt_pmic_regulator/ldo_regulators/ldo_vusb";
		mt_pmic_vgp1_ldo_reg = "/mt_pmic_regulator/ldo_regulators/ldo_vgp1";
		mt_pmic_vgp2_ldo_reg = "/mt_pmic_regulator/ldo_regulators/ldo_vgp2";
		mt_pmic_vemc_3v3_ldo_reg = "/mt_pmic_regulator/ldo_regulators/ldo_vemc_3v3";
		mt_pmic_vcamaf_ldo_reg = "/mt_pmic_regulator/ldo_regulators/ldo_vcamaf";
		mt_pmic_vmc_ldo_reg = "/mt_pmic_regulator/ldo_regulators/ldo_vmc";
		mt_pmic_vmch_ldo_reg = "/mt_pmic_regulator/ldo_regulators/ldo_vmch";
		mt_pmic_vibr_ldo_reg = "/mt_pmic_regulator/ldo_regulators/ldo_vibr";
		mt_pmic_vrtc_ldo_reg = "/mt_pmic_regulator/ldo_regulators/ldo_vrtc";
		mt_pmic_vm_ldo_reg = "/mt_pmic_regulator/ldo_regulators/ldo_vm";
		mt_pmic_vrf18_ldo_reg = "/mt_pmic_regulator/ldo_regulators/ldo_vrf18";
		mt_pmic_vio18_ldo_reg = "/mt_pmic_regulator/ldo_regulators/ldo_vio18";
		mt_pmic_vcamd_ldo_reg = "/mt_pmic_regulator/ldo_regulators/ldo_vcamd";
		mt_pmic_vcamio_ldo_reg = "/mt_pmic_regulator/ldo_regulators/ldo_vcamio";
		mt_pmic_vgp3_ldo_reg = "/mt_pmic_regulator/ldo_regulators/ldo_vgp3";
		mt_pmic_vcn_1v8_ldo_reg = "/mt_pmic_regulator/ldo_regulators/ldo_vcn_1v8";
		mt_pmic_vcanio_ldo_reg = "/mt_pmic_regulator/ldo_regulators/vcanio_ldo_reg";
		mt_pmic_vcn33_ldo_reg = "/mt_pmic_regulator/ldo_regulators/vcn33_ldo_reg";
		rf_clock_buffer_ctrl = "/rf_clock_buffer";
		odm = "/odm";
	};
};
